AUTOSAR XML (schema 4-1-3)
standard types defined: boolean, uint16, uint32, uint8
package /UAES/ASW/CompuMethods
  compu method CM_boolean: 0=FALSE, 1=TRUE
package /UAES/ASW/DataConstrs
  range DC_boolean: raw 0..1
  range DC_uint16: raw 0..65535
  range DC_uint32: raw 0..4294967295
  range DC_uint8: raw 0..255
package /UAES/ASW/DataTypeMappingSets
  data type mapping set EFuse_ComCnvTx
package /UAES/ASW/ImplementationDataTypes
  impl type rt_Array_uint32_9: category=ARRAY, sw-calibration-access=READ-ONLY, type-emitter=RTE
    element rt_Array_uint32_9: array-size=9, array-size-semantics=FIXED-SIZE, implementation-data-type=uint32
package /UAES/ASW/PortInterfaces
  13 x sender receiver interface:
    ComTx_bIPDS_ADCBackup1PowerSt: invalidation-policy{data-element=ComTx_bIPDS_ADCBackup1PowerSt/Val, handle-invalid=DONT-INVALIDATE}
      data Val: sw-calibration-access=READ-ONLY, type=boolean
    ComTx_bIPDS_ADCBackup2PowerSt: invalidation-policy{data-element=ComTx_bIPDS_ADCBackup2PowerSt/Val, handle-invalid=DONT-INVALIDATE}
      data Val: sw-calibration-access=READ-ONLY, type=boolean
    ComTx_bIPDS_RearDCDCPowerSt: invalidation-policy{data-element=ComTx_bIPDS_RearDCDCPowerSt/Val, handle-invalid=DONT-INVALIDATE}
      data Val: sw-calibration-access=READ-ONLY, type=boolean
    ComTx_u16IPDS_ADCBackup1PowerCurrent: invalidation-policy{data-element=ComTx_u16IPDS_ADCBackup1PowerCurrent/Val, handle-invalid=DONT-INVALIDATE}
      data Val: sw-calibration-access=READ-ONLY, type=uint16
    ComTx_u16IPDS_ADCBackup2PowerCurrent: invalidation-policy{data-element=ComTx_u16IPDS_ADCBackup2PowerCurrent/Val, handle-invalid=DONT-INVALIDATE}
      data Val: sw-calibration-access=READ-ONLY, type=uint16
    ComTx_u16IPDS_RearDCDCPowerCurrent: invalidation-policy{data-element=ComTx_u16IPDS_RearDCDCPowerCurrent/Val, handle-invalid=DONT-INVALIDATE}
      data Val: sw-calibration-access=READ-ONLY, type=uint16
    ComTx_u8IPDS_ADCBackup1PowerFaultSt: invalidation-policy{data-element=ComTx_u8IPDS_ADCBackup1PowerFaultSt/Val, handle-invalid=DONT-INVALIDATE}
      data Val: sw-calibration-access=READ-ONLY, type=uint8
    ComTx_u8IPDS_ADCBackup2PowerFaultSt: invalidation-policy{data-element=ComTx_u8IPDS_ADCBackup2PowerFaultSt/Val, handle-invalid=DONT-INVALIDATE}
      data Val: sw-calibration-access=READ-ONLY, type=uint8
    ComTx_u8IPDS_RearDCDCPowerFaultSt: invalidation-policy{data-element=ComTx_u8IPDS_RearDCDCPowerFaultSt/Val, handle-invalid=DONT-INVALIDATE}
      data Val: sw-calibration-access=READ-ONLY, type=uint8
    EFuse_au32CurrFild: invalidation-policy{data-element=EFuse_au32CurrFild/Val, handle-invalid=DONT-INVALIDATE}
      data Val: sw-calibration-access=READ-ONLY, type=rt_Array_uint32_9
    EFuse_au32ErrInfo: invalidation-policy{data-element=EFuse_au32ErrInfo/Val, handle-invalid=DONT-INVALIDATE}
      data Val: sw-calibration-access=READ-ONLY, type=rt_Array_uint32_9
    EFuse_flgAllwSleep: invalidation-policy{data-element=EFuse_flgAllwSleep/Val, handle-invalid=DONT-INVALIDATE}
      data Val: sw-calibration-access=READ-ONLY, type=boolean
    gEFUSE_u32AllowSleep_Local: invalidation-policy{data-element=gEFUSE_u32AllowSleep_Local/Val, handle-invalid=DONT-INVALIDATE}
      data Val: sw-calibration-access=READ-ONLY, type=uint32
package /UAES/ASW/SwComponentTypes
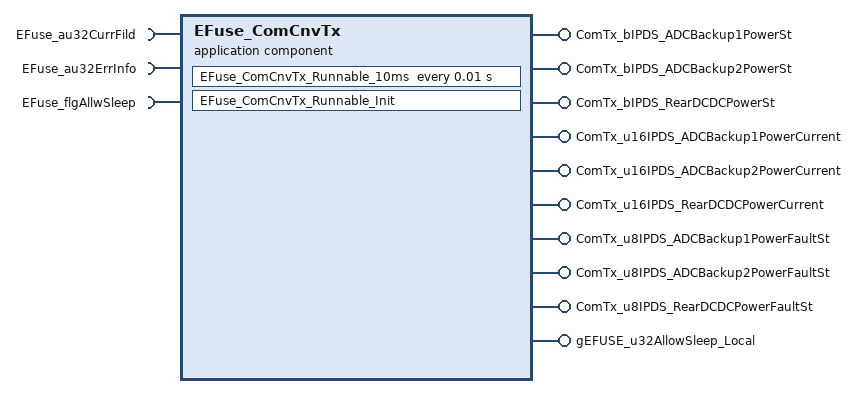
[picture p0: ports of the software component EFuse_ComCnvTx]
  application sw component type EFuse_ComCnvTx
    10 x provide port:
      ComTx_bIPDS_ADCBackup1PowerSt: nonqueued-sender-com-spec{data-element=ComTx_bIPDS_ADCBackup1PowerSt/Val, init-value=0}, provided-interface=ComTx_bIPDS_ADCBackup1PowerSt
      ComTx_bIPDS_ADCBackup2PowerSt: nonqueued-sender-com-spec{data-element=ComTx_bIPDS_ADCBackup2PowerSt/Val, init-value=0}, provided-interface=ComTx_bIPDS_ADCBackup2PowerSt
      ComTx_bIPDS_RearDCDCPowerSt: nonqueued-sender-com-spec{data-element=ComTx_bIPDS_RearDCDCPowerSt/Val, init-value=0}, provided-interface=ComTx_bIPDS_RearDCDCPowerSt
      ComTx_u16IPDS_ADCBackup1PowerCurrent: nonqueued-sender-com-spec{data-element=ComTx_u16IPDS_ADCBackup1PowerCurrent/Val, init-value=0}, provided-interface=ComTx_u16IPDS_ADCBackup1PowerCurrent
      ComTx_u16IPDS_ADCBackup2PowerCurrent: nonqueued-sender-com-spec{data-element=ComTx_u16IPDS_ADCBackup2PowerCurrent/Val, init-value=0}, provided-interface=ComTx_u16IPDS_ADCBackup2PowerCurrent
      ComTx_u16IPDS_RearDCDCPowerCurrent: nonqueued-sender-com-spec{data-element=ComTx_u16IPDS_RearDCDCPowerCurrent/Val, init-value=0}, provided-interface=ComTx_u16IPDS_RearDCDCPowerCurrent
      ComTx_u8IPDS_ADCBackup1PowerFaultSt: nonqueued-sender-com-spec{data-element=ComTx_u8IPDS_ADCBackup1PowerFaultSt/Val, init-value=0}, provided-interface=ComTx_u8IPDS_ADCBackup1PowerFaultSt
      ComTx_u8IPDS_ADCBackup2PowerFaultSt: nonqueued-sender-com-spec{data-element=ComTx_u8IPDS_ADCBackup2PowerFaultSt/Val, init-value=0}, provided-interface=ComTx_u8IPDS_ADCBackup2PowerFaultSt
      ComTx_u8IPDS_RearDCDCPowerFaultSt: nonqueued-sender-com-spec{data-element=ComTx_u8IPDS_RearDCDCPowerFaultSt/Val, init-value=0}, provided-interface=ComTx_u8IPDS_RearDCDCPowerFaultSt
      gEFUSE_u32AllowSleep_Local: nonqueued-sender-com-spec{data-element=gEFUSE_u32AllowSleep_Local/Val, init-value=0}, provided-interface=gEFUSE_u32AllowSleep_Local
    require port EFuse_au32CurrFild: nonqueued-receiver-com-spec{data-element=EFuse_au32CurrFild/Val, filter=data-filter-type=ALWAYS, init-value=9 x 0}, required-interface=EFuse_au32CurrFild
    require port EFuse_au32ErrInfo: nonqueued-receiver-com-spec{data-element=EFuse_au32ErrInfo/Val, filter=data-filter-type=ALWAYS, init-value=9 x 0}, required-interface=EFuse_au32ErrInfo
    require port EFuse_flgAllwSleep: nonqueued-receiver-com-spec{data-element=EFuse_flgAllwSleep/Val, filter=data-filter-type=ALWAYS, init-value=0}, required-interface=EFuse_flgAllwSleep
    behavior EFuse_ComCnvTx_InternalBehavior: data-type-mapping=EFuse_ComCnvTx
      timing event TMT_EFuse_ComCnvTx_Runnable_10ms: start-on-event=EFuse_ComCnvTx_Runnable_10ms, period=0.01
      init event EFuse_ComCnvTx_Runnable_InitEvent: start-on-event=EFuse_ComCnvTx_Runnable_Init
      runnable EFuse_ComCnvTx_Runnable_10ms
        data-read-access:
          access READ_EFuse_au32CurrFild_Val: accessed-variable=EFuse_au32CurrFild.Val
          access READ_EFuse_au32ErrInfo_Val: accessed-variable=EFuse_au32ErrInfo.Val
          access READ_EFuse_flgAllwSleep_Val: accessed-variable=EFuse_flgAllwSleep.Val
        data-write-access:
          10 x access:
            WRITE_ComTx_bIPDS_ADCBackup1PowerSt_Val: accessed-variable=ComTx_bIPDS_ADCBackup1PowerSt.Val
            WRITE_ComTx_bIPDS_ADCBackup2PowerSt_Val: accessed-variable=ComTx_bIPDS_ADCBackup2PowerSt.Val
            WRITE_ComTx_bIPDS_RearDCDCPowerSt_Val: accessed-variable=ComTx_bIPDS_RearDCDCPowerSt.Val
            WRITE_ComTx_u16IPDS_ADCBackup1PowerCurrent_Val: accessed-variable=ComTx_u16IPDS_ADCBackup1PowerCurrent.Val
            WRITE_ComTx_u16IPDS_ADCBackup2PowerCurrent_Val: accessed-variable=ComTx_u16IPDS_ADCBackup2PowerCurrent.Val
            WRITE_ComTx_u16IPDS_RearDCDCPowerCurrent_Val: accessed-variable=ComTx_u16IPDS_RearDCDCPowerCurrent.Val
            WRITE_ComTx_u8IPDS_ADCBackup1PowerFaultSt_Val: accessed-variable=ComTx_u8IPDS_ADCBackup1PowerFaultSt.Val
            WRITE_ComTx_u8IPDS_ADCBackup2PowerFaultSt_Val: accessed-variable=ComTx_u8IPDS_ADCBackup2PowerFaultSt.Val
            WRITE_ComTx_u8IPDS_RearDCDCPowerFaultSt_Val: accessed-variable=ComTx_u8IPDS_RearDCDCPowerFaultSt.Val
            WRITE_gEFUSE_u32AllowSleep_Local_Val: accessed-variable=gEFUSE_u32AllowSleep_Local.Val
      runnable EFuse_ComCnvTx_Runnable_Init
  swc implementation EFuse_ComCnvTx_Implementation: behavior=EFuse_ComCnvTx_InternalBehavior
    code-descriptors:
      code Default: artifact-descriptors=autosar-engineering-object={short-label=Default, category=SWSRC}
package /UAES/ASW/Units
  unit NoUnit: factor-si-to-unit=1, offset-si-to-unit=0
